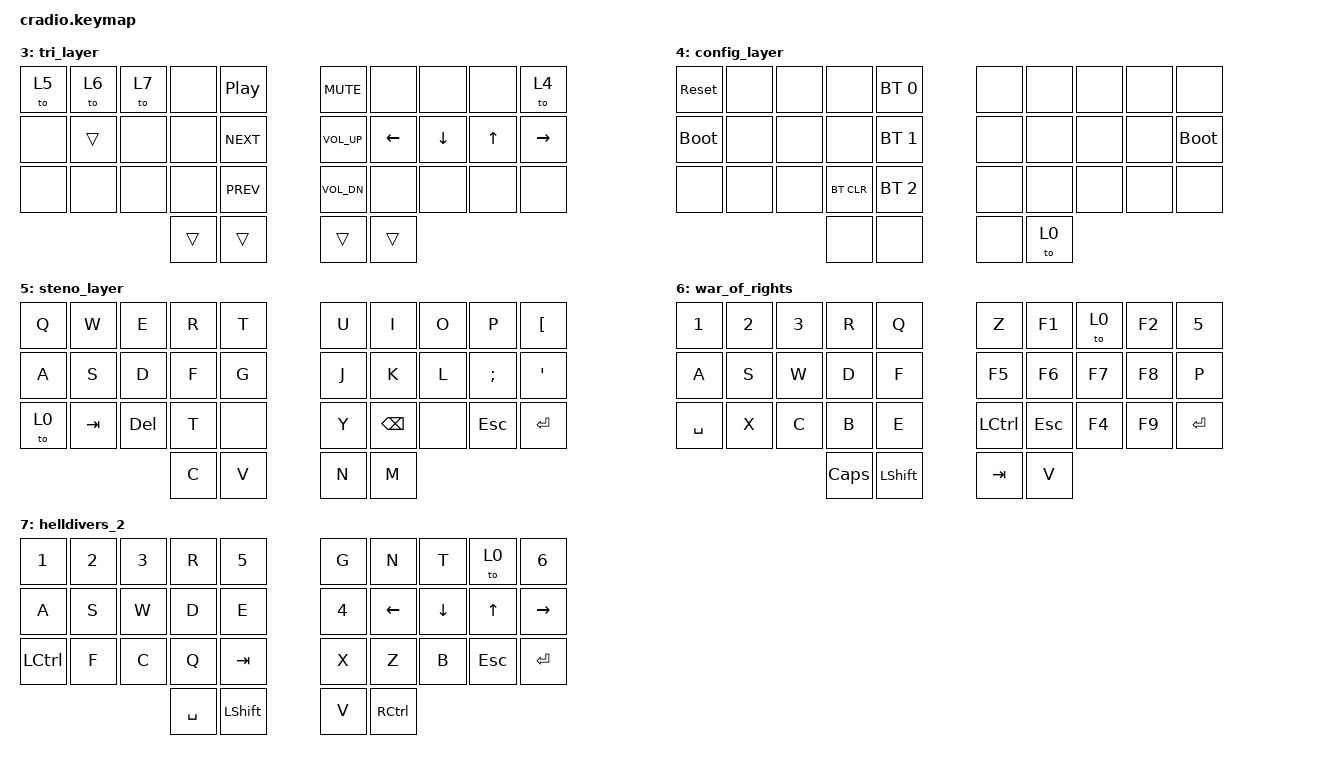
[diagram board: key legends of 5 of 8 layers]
// Copyright (c) 2022 The ZMK Contributors
// SPDX-License-Identifier: MIT

#include <behaviors.dtsi>
#include <dt-bindings/zmk/keys.h>
#include <dt-bindings/zmk/bt.h>

// Home row mods macro
#define HRML(k1,k2,k3) &ht LGUI k1  &ht LALT k2  &ht LCTRL k3
#define HRMR(k1,k2,k3) &ht RCTRL k1  &ht RALT k2  &ht RGUI k3

/ {
    behaviors {
        ht: hold_tap {
            compatible = "zmk,behavior-hold-tap";
            #binding-cells = <2>;
            flavor = "tap-preferred";
            tapping-term-ms = <220>;
            quick-tap-ms = <150>;
            require-prior-idle-ms = <100>;
            bindings = <&kp>, <&kp>;
        };
    };

    conditional_layers {
        compatible = "zmk,conditional-layers";
        tri_layer {
            if-layers = <1 2>;
            then-layer = <3>;
        };
    };

    keymap {
        compatible = "zmk,keymap";
        default_layer {
            bindings = <
        //╭──────────┬──────────┬──────────┬──────────┬──────────╮   ╭──────────┬──────────┬──────────┬──────────┬──────────╮
        //│  DELETE  │  W       │  F       │  P       │  B       │   │  J       │  L       │  U       │  Y       │  BACKSP  │
            &kp DEL    &kp W      &kp F      &kp P      &kp B          &kp J      &kp L      &kp U      &kp Y      &kp BSPC
        //├──────────┼──────────┼──────────┼──────────┼──────────┤   ├──────────┼──────────┼──────────┼──────────┼──────────┤
        //│  A       │  R       │  S       │  T       │  G       │   │  M       │  N       │  E       │  I       │  O       │
            HRML(A,        R,         S)     &kp T      &kp G          &kp M      &kp N      HRMR(E,         I,        O)
        //├──────────┼──────────┼──────────┼──────────┼──────────┤   ├──────────┼──────────┼──────────┼──────────┼──────────┤
        //│  Z       │  X       │  C       │  D       │  V       │   │  K       │  H       │  Q       │ ; :      │ ' "      │
            &kp Z      &kp X      &kp C      &kp D      &kp V          &kp K      &kp H      &kp Q      &kp SEMI   &kp SQT
        //╰──────────┴──────────┴──────────┼──────────┼──────────┤   ├──────────┼──────────┼──────────┴──────────┴──────────╯
                                      &lt 2 ENTER  &ht LSHIFT SPACE  &ht LSHIFT SPACE  &lt 1 ESC
        //                                 ╰──────────┴──────────╯   ╰──────────┴──────────╯
            >;
        };

        right_layer {
            bindings = <
        //╭──────────┬──────────┬──────────┬──────────┬──────────╮   ╭──────────┬──────────┬──────────┬──────────┬──────────╮
        //│          │          │ \ |      │ ` ~      │          │   │ CALC     │ 7 &      │ 8 *      │ 9 (      │          │
            &trans     &none      &kp BSLH   &kp GRAVE  &none       &kp C_AL_CALC &kp N7     &kp N8     &kp N9     &trans
        //├──────────┼──────────┼──────────┼──────────┼──────────┤   ├──────────┼──────────┼──────────┼──────────┼──────────┤
        //│ [ {      │ ] }      │ - _      │  +       │ = +      │   │ 0 )      │ 4 $      │ 5 %      │ 6 ^      │ . >      │
            HRML(LBKT,   RBKT,     MINUS)    &kp PLUS   &kp EQUAL      &kp N0     &kp N4     HRMR(N5,      N6,       DOT)
        //├──────────┼──────────┼──────────┼──────────┼──────────┤   ├──────────┼──────────┼──────────┼──────────┼──────────┤
        //│ (        │  )       │  / ?     │  *       │  TAB     │   │          │ 1 !      │ 2 @      │ 3 #      │ , <      │
           &kp LPAR    &kp RPAR   &kp FSLH   &kp STAR   &kp TAB        &none      &kp N1     &kp N2     &kp N3     &kp COMMA
        //╰──────────┴──────────┴──────────┼──────────┼──────────┤   ├──────────┼──────────┼──────────┴──────────┴──────────╯
                                             &trans     &trans        &trans     &trans
        //                                 ╰──────────┴──────────╯   ╰──────────┴──────────╯
            >;
        };

        left_layer {
            bindings = <
        //╭──────────┬──────────┬──────────┬──────────┬──────────╮   ╭──────────┬──────────┬──────────┬──────────┬──────────╮
        //│  F1      │  F2      │  F3      │  F4      │          │   │          │  PrnScr  │  CAPS    │  NumLock │          │
            &kp F1     &kp F2     &kp F3     &kp F4     &none          &none      &kp PSCRN  &kp CAPS   &kp KP_NUM &none
        //├──────────┼──────────┼──────────┼──────────┼──────────┤   ├──────────┼──────────┼──────────┼──────────┼──────────┤
        //│  F5      │  F6      │  F7      │  F8      │          │   │  TAB     │  LEFT    │  DOWN    │  UP      │  RIGHT   │
            HRML(F5,      F6,        F7)     &kp F8     &none          &kp TAB    &kp LEFT   HRMR(DOWN,    UP,      RIGHT)
        //├──────────┼──────────┼──────────┼──────────┼──────────┤   ├──────────┼──────────┼──────────┼──────────┼──────────┤
        //│  F9      │  F10     │  F11     │  F12     │          │   │          │  HOME    │  PG DWN  │  PG UP   │  END     │
            &kp F9     &kp F10    &kp F11    &kp F12    &none          &none      &kp HOME   &kp PG_DN  &kp PG_UP  &kp END
        //╰──────────┴──────────┴──────────┼──────────┼──────────┤   ├──────────┼──────────┼──────────┴──────────┴──────────╯
                                             &trans     &trans         &trans     &trans
        //                                 ╰──────────┴──────────╯   ╰──────────┴──────────╯
            >;
        };

        tri_layer {
            bindings = <
        //╭──────────┬──────────┬──────────┬──────────┬──────────╮   ╭──────────┬──────────┬──────────┬──────────┬──────────╮
        //│          │          │          │          │ PAUSE    │   │  MUTE    │          │          │          │          │
            &to 5      &to 6      &to 7      &none     &kp C_PP       &kp C_MUTE  &none      &none      &none      &to 4
        //├──────────┼──────────┼──────────┼──────────┼──────────┤   ├──────────┼──────────┼──────────┼──────────┼──────────┤
        //│          │          │          │NEXT TRACK│   │          │  VOL UP  │  LEFT    │  DOWN    │  UP      │  RIGHT   │
            &none      &trans     &none      &none     &kp C_NEXT    &kp C_VOL_UP &kp LEFT   &kp DOWN   &kp UP     &kp RIGHT
        //├──────────┼──────────┼──────────┼──────────┼──────────┤   ├──────────┼──────────┼──────────┼──────────┼──────────┤
        //│          │          │          │          │PREV TRACK│   │  VOL DOWN│          │          │          │          │
            &none      &none      &none      &none     &kp C_PREV    &kp C_VOL_DN &none      &none      &none      &none
        //╰──────────┴──────────┴──────────┼──────────┼──────────┤   ├──────────┼──────────┼──────────┴──────────┴──────────╯
                                             &trans     &trans         &trans     &trans
        //                                 ╰──────────┴──────────╯   ╰──────────┴──────────╯
            >;
        };        

        config_layer {
            bindings = <
        //╭──────────┬──────────┬──────────┬──────────┬──────────╮   ╭──────────┬──────────┬──────────┬──────────┬──────────╮
        //│  RESET   │          │          │          │PROFILE 0 │   │          │          │          │          │          │
           &sys_reset  &none      &none      &none     &bt BT_SEL 0    &none      &none      &none      &none      &none
        //├──────────┼──────────┼──────────┼──────────┼──────────┤   ├──────────┼──────────┼──────────┼──────────┼──────────┤
        //│BOOTLOADER│          │          │          │PROFILE 1 │   │          │          │          │          │BOOTLOADER│
          &bootloader  &none      &none      &none     &bt BT_SEL 1    &none      &none      &none      &none     &bootloader
        //├──────────┼──────────┼──────────┼──────────┼──────────┤   ├──────────┼──────────┼──────────┼──────────┼──────────┤
        //│          │          │          │ CLEAR BT │PROFILE 2 │   │          │          │          │          │          │
            &none      &none      &none     &bt BT_CLR &bt BT_SEL 2    &none      &none      &none      &none      &none 
        //╰──────────┴──────────┴──────────┼──────────┼──────────┤   ├──────────┼──────────┼──────────┴──────────┴──────────╯
                                             &none      &none          &none      &to 0
        //                                 ╰──────────┴──────────╯   ╰──────────┴──────────╯
            >;
        };

        steno_layer {
            bindings = <
        //╭──────────┬──────────┬──────────┬──────────┬──────────╮   ╭──────────┬──────────┬──────────┬──────────┬──────────╮
        //│  Q       │  W       │  E       │  R       │  T       │   │  U       │  I       │  O       │  P       │ [ {      │
            &kp Q      &kp W      &kp E      &kp R      &kp T          &kp U      &kp I      &kp O      &kp P      &kp LBKT
        //├──────────┼──────────┼──────────┼──────────┼──────────┤   ├──────────┼──────────┼──────────┼──────────┼──────────┤
        //│  A       │  S       │  D       │  F       │  G       │   │  J       │  K       │  L       │  ; :     │  ' "     │
            &kp A      &kp S      &kp D      &kp F      &kp G          &kp J      &kp K      &kp L      &kp SEMI   &kp SQT
        //├──────────┼──────────┼──────────┼──────────┼──────────┤   ├──────────┼──────────┼──────────┼──────────┼──────────┤
        //│          │  TAB     │  DELETE  │  T       │          │   │  Y       │  BCKSP   │          │  ESCAPE  │  ENTER   │
            &to 0      &kp TAB    &kp DEL    &kp T      &none          &kp Y      &kp BSPC   &none      &kp ESC    &kp ENTER 
        //╰──────────┴──────────┴──────────┼──────────┼──────────┤   ├──────────┼──────────┼──────────┴──────────┴──────────╯
                                             &kp C      &kp V          &kp N      &kp M
        //                                 ╰──────────┴──────────╯   ╰──────────┴──────────╯
            >;
        };

        war_of_rights {
            bindings = <
        //╭──────────┬──────────┬──────────┬──────────┬──────────╮   ╭──────────┬──────────┬──────────┬──────────┬──────────╮
        //│  1       │  2       │  3       │  R       │  Q       │   │  Z       │  F1      │  OUT     │  F2      │  5       │
            &kp N1     &kp N2     &kp N3     &kp R      &kp Q          &kp Z      &kp F1     &to 0      &kp F2      &kp N5
        //├──────────┼──────────┼──────────┼──────────┼──────────┤   ├──────────┼──────────┼──────────┼──────────┼──────────┤
        //│  A       │  S       │  W       │  D       │  F       │   │  F5      │  F6      │  F7      │  F8      │  P       │
            &kp A      &kp S      &kp W      &kp D      &kp F          &kp F5     &kp F6     &kp F7     &kp F8     &kp P
        //├──────────┼──────────┼──────────┼──────────┼──────────┤   ├──────────┼──────────┼──────────┼──────────┼──────────┤
        //│  SPACE   │  X       │  C       │  B       │  E       │   │  CTRL    │  ESC     │  F4      │  F9      │  ENTER   │
            &kp SPACE  &kp X      &kp C      &kp B      &kp E          &kp LCTRL  &kp ESC    &kp F4     &kp F9     &kp ENTER 
        //╰──────────┴──────────┴──────────┼──────────┼──────────┤   ├──────────┼──────────┼──────────┴──────────┴──────────╯
                                             &kp CAPS   &kp LSHIFT      &kp TAB    &kp V
        //                                 ╰──────────┴──────────╯   ╰──────────┴──────────╯
            >;
        };

        helldivers_2 {
            bindings = <
        //╭──────────┬──────────┬──────────┬──────────┬──────────╮   ╭──────────┬──────────┬──────────┬──────────┬──────────╮
        //│  1       │  2       │  3       │  R       │  5       │   │  G       │          │          │  OUT     │          │
            &kp N1     &kp N2     &kp N3     &kp R      &kp N5         &kp G      &kp N      &kp T      &to 0      &kp N6
        //├──────────┼──────────┼──────────┼──────────┼──────────┤   ├──────────┼──────────┼──────────┼──────────┼──────────┤
        //│  A       │  S       │  W       │  D       │  E       │   │  4       │  LEFT    │  DOWN    │  UP      │  RIGHT   │
            &kp A      &kp S      &kp W      &kp D      &kp E          &kp N4     &kp LEFT   &kp DOWN   &kp UP     &kp RIGHT
        //├──────────┼──────────┼──────────┼──────────┼──────────┤   ├──────────┼──────────┼──────────┼──────────┼──────────┤
        //│  CTRL    │  F       │  C       │  Q       │  TAB     │   │  X       │  Z       │  B       │  ESC     │  ENTER   │
            &kp LCTRL  &kp F      &kp C      &kp Q      &kp TAB        &kp X      &kp Z      &kp B      &kp ESC     &kp ENTER 
        //╰──────────┴──────────┴──────────┼──────────┼──────────┤   ├──────────┼──────────┼──────────┴──────────┴──────────╯
                                            &kp SPACE   &kp LSHIFT     &kp V      &kp RCTRL
        //                                 ╰──────────┴──────────╯   ╰──────────┴──────────╯
            >;
        };
    };
};
